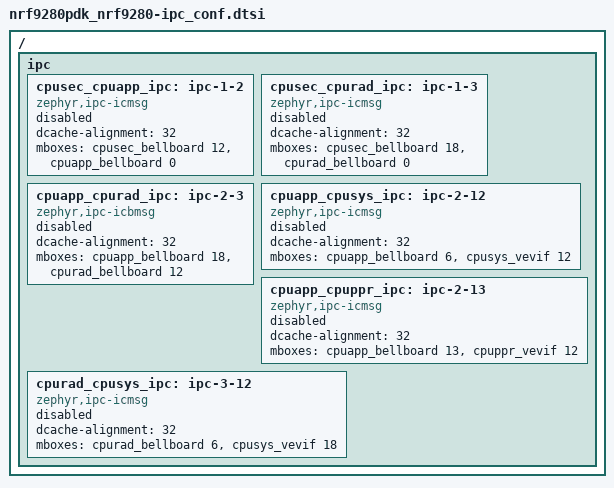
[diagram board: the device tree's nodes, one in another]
/*
 * Copyright (c) 2024 Nordic Semiconductor ASA
 *
 * SPDX-License-Identifier: Apache-2.0
 */

/ {
	ipc {
		cpusec_cpuapp_ipc: ipc-1-2 {
			compatible = "zephyr,ipc-icmsg";
			dcache-alignment = <32>;
			mboxes = <&cpusec_bellboard 12>,
				 <&cpuapp_bellboard 0>;
			status = "disabled";
		};

		cpusec_cpurad_ipc: ipc-1-3 {
			compatible = "zephyr,ipc-icmsg";
			dcache-alignment = <32>;
			mboxes = <&cpusec_bellboard 18>,
				 <&cpurad_bellboard 0>;
			status = "disabled";
		};

		cpuapp_cpurad_ipc: ipc-2-3 {
			compatible = "zephyr,ipc-icbmsg";
			dcache-alignment = <32>;
			mboxes = <&cpuapp_bellboard 18>,
				 <&cpurad_bellboard 12>;
			status = "disabled";
		};

		cpuapp_cpusys_ipc: ipc-2-12 {
			compatible = "zephyr,ipc-icmsg";
			dcache-alignment = <32>;
			mboxes = <&cpuapp_bellboard 6>,
				 <&cpusys_vevif 12>;
			status = "disabled";
		};

		cpuapp_cpuppr_ipc: ipc-2-13 {
			compatible = "zephyr,ipc-icmsg";
			dcache-alignment = <32>;
			mboxes = <&cpuapp_bellboard 13>,
				 <&cpuppr_vevif 12>;
			status = "disabled";
		};

		cpurad_cpusys_ipc: ipc-3-12 {
			compatible = "zephyr,ipc-icmsg";
			dcache-alignment = <32>;
			mboxes = <&cpurad_bellboard 6>,
				 <&cpusys_vevif 18>;
			status = "disabled";
		};
	};
};
